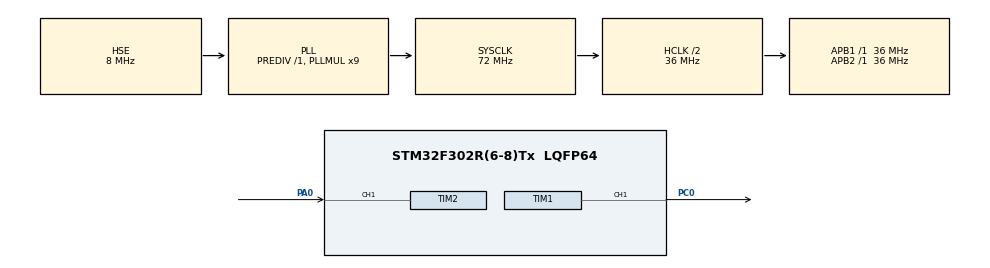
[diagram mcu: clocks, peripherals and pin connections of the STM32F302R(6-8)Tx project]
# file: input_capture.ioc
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Mcu.Family=STM32F3
Mcu.Name=STM32F302R(6-8)Tx
Mcu.Package=LQFP64
NVIC.PriorityGroup=NVIC_PRIORITYGROUP_0
NVIC.TIM2_IRQn=true\:0\:0\:false\:false\:true\:true\:true\:true
PA0.Signal=S_TIM2_CH1_ETR
PA13.GPIO_Label=TMS
PA13.Mode=Serial_Wire
PA13.Signal=SYS_JTMS-SWDIO
PA14.GPIO_Label=TCK
PA14.Mode=Serial_Wire
PA14.Signal=SYS_JTCK-SWCLK
PC0.Signal=S_TIM1_CH1
PC14\ -\ OSC32_IN.Mode=LSE-External-Clock-Source
PC14\ -\ OSC32_IN.Signal=RCC_OSC32_IN
PF0-OSC_IN.Mode=HSE-External-Oscillator
PF0-OSC_IN.Signal=RCC_OSC_IN
PF1-OSC_OUT.Mode=HSE-External-Oscillator
PF1-OSC_OUT.Signal=RCC_OSC_OUT
ProjectManager.HeapSize=0x200
ProjectManager.StackSize=0x400
ProjectManager.TargetToolchain=STM32CubeIDE
RCC.AHBCLKDivider=RCC_SYSCLK_DIV2
RCC.AHBFreq_Value=36000000
RCC.APB1Freq_Value=36000000
RCC.APB1TimFreq_Value=36000000
RCC.APB2Freq_Value=36000000
RCC.APB2TimFreq_Value=36000000
RCC.CortexFreq_Value=36000000
RCC.HCLKFreq_Value=36000000
RCC.HSE_VALUE=8000000
RCC.HSI_VALUE=8000000
RCC.LSE_VALUE=32768
RCC.PLLM=8
RCC.PLLMUL=RCC_PLL_MUL9
RCC.PLLN=336
RCC.PLLP=RCC_PLLP_DIV4
RCC.PLLQ=7
RCC.PLLSourceVirtual=RCC_PLLSOURCE_HSE
RCC.SYSCLKFreq_VALUE=72000000
RCC.SYSCLKSourceVirtual=RCC_SYSCLKSOURCE_PLLCLK
RCC.USBFreq_Value=72000000
SH.S_TIM1_CH1.0=TIM1_CH1,PWM Generation1 CH1
SH.S_TIM2_CH1_ETR.0=TIM2_CH1,Input_Capture1_from_TI1
TIM1.AutoReloadPreload=TIM_AUTORELOAD_PRELOAD_ENABLE
TIM1.Channel-PWM\ Generation1\ CH1=TIM_CHANNEL_1
TIM1.OC1Preload_PWM=ENABLE
TIM1.Prescaler=71
TIM1.Pulse-PWM\ Generation1\ CH1=25
TIM2.Channel-Input_Capture1_from_TI1=TIM_CHANNEL_1
VP_TIM1_VS_ClockSourceINT.Mode=Internal
VP_TIM2_VS_ClockSourceINT.Mode=Internal
board=NUCLEO-F302R8

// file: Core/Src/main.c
/* USER CODE BEGIN Header */
/**
  ******************************************************************************
  * @file           : main.c
  * @brief          : Main program body
  ******************************************************************************
  * @attention
  *
  * Copyright (c) 2026 STMicroelectronics.
  * All rights reserved.
  *
  * This software is licensed under terms that can be found in the LICENSE file
  * in the root directory of this software component.
  * If no LICENSE file comes with this software, it is provided AS-IS.
  *
  ******************************************************************************
  */
/* USER CODE END Header */
#include "main.h"
#include "tim.h"
#include "gpio.h"

/* USER CODE BEGIN PV */
uint32_t rise = 0;
int first_Capture = 0;
uint32_t rise1 = 0;
uint32_t diff = 0;
float frequency = 0.0;
float tim_Clock = 0.0;
float time_Period =0.0;

/* USER CODE END PV */

void SystemClock_Config(void);

int main(void)
{

  /* MCU Configuration--------------------------------------------------------*/

  /* Reset of all peripherals, Initializes the Flash interface and the Systick. */
  HAL_Init();

  /* Configure the system clock */
  SystemClock_Config();

  /* Initialize all configured peripherals */
  MX_GPIO_Init();
  MX_TIM1_Init();
  MX_TIM2_Init();
  /* USER CODE BEGIN 2 */
  HAL_TIM_PWM_Start(&htim1, TIM_CHANNEL_1);
  HAL_TIM_IC_Start_IT(&htim2, TIM_CHANNEL_1);

  /* USER CODE END 2 */

  /* Infinite loop */
  while (1)
  {

  }
}

void SystemClock_Config(void)
{
  RCC_OscInitTypeDef RCC_OscInitStruct = {0};
  RCC_ClkInitTypeDef RCC_ClkInitStruct = {0};
  RCC_PeriphCLKInitTypeDef PeriphClkInit = {0};

  /** Initializes the RCC Oscillators according to the specified parameters
  * in the RCC_OscInitTypeDef structure.
  */
  RCC_OscInitStruct.OscillatorType = RCC_OSCILLATORTYPE_HSE;
  RCC_OscInitStruct.HSEState = RCC_HSE_ON;
  RCC_OscInitStruct.HSEPredivValue = RCC_HSE_PREDIV_DIV1;
  RCC_OscInitStruct.HSIState = RCC_HSI_ON;
  RCC_OscInitStruct.PLL.PLLState = RCC_PLL_ON;
  RCC_OscInitStruct.PLL.PLLSource = RCC_PLLSOURCE_HSE;
  RCC_OscInitStruct.PLL.PLLMUL = RCC_PLL_MUL9;
  if (HAL_RCC_OscConfig(&RCC_OscInitStruct) != HAL_OK)
  {
    Error_Handler();
  }

  /** Initializes the CPU, AHB and APB buses clocks
  */
  RCC_ClkInitStruct.ClockType = RCC_CLOCKTYPE_HCLK|RCC_CLOCKTYPE_SYSCLK
                              |RCC_CLOCKTYPE_PCLK1|RCC_CLOCKTYPE_PCLK2;
  RCC_ClkInitStruct.SYSCLKSource = RCC_SYSCLKSOURCE_PLLCLK;
  RCC_ClkInitStruct.AHBCLKDivider = RCC_SYSCLK_DIV2;
  RCC_ClkInitStruct.APB1CLKDivider = RCC_HCLK_DIV1;
  RCC_ClkInitStruct.APB2CLKDivider = RCC_HCLK_DIV1;

  if (HAL_RCC_ClockConfig(&RCC_ClkInitStruct, FLASH_LATENCY_1) != HAL_OK)
  {
    Error_Handler();
  }
  PeriphClkInit.PeriphClockSelection = RCC_PERIPHCLK_TIM1;
  PeriphClkInit.Tim1ClockSelection = RCC_TIM1CLK_HCLK;
  if (HAL_RCCEx_PeriphCLKConfig(&PeriphClkInit) != HAL_OK)
  {
    Error_Handler();
  }
}

/* USER CODE BEGIN 4 */
void HAL_TIM_IC_CaptureCallback(TIM_HandleTypeDef *htim)
{
	// Measuring Frequency
	if(htim->Channel == HAL_TIM_ACTIVE_CHANNEL_1)
	{
		if(first_Capture == 0)  // if rising edge is not captured
		{
			rise = HAL_TIM_ReadCapturedValue(htim, TIM_CHANNEL_1);
			first_Capture = 1;
		}
		else                    // capture next rising edge - calc period
		{
			rise1 = HAL_TIM_ReadCapturedValue(htim, TIM_CHANNEL_1);
			if(rise1 > rise)
			{
			    diff = rise1 - rise;
			}
			else if (rise > rise1)
			{
				diff = (0xffffffff - rise) + rise1 + 1;
			}
			tim_Clock = (36000000.0f)/(72);   // timer clock = (36Mhz)/(PSC+1)
			frequency = tim_Clock / diff ;
			time_Period = 1/frequency;

			first_Capture = 0 ;

		}
	}
}

/* USER CODE END 4 */

void Error_Handler(void)
{
  __disable_irq();
  while (1)
  {
  }
}
